# iospear600 register map
Registers are 32-bit, access not given, no defined reset value unless marked. A register's access mark holds for its fields unless they carry their own. Addresses are absolute; registers are grouped by the start of their names; [hi:lo] are bit positions; {n}, {i} and the like mark numbered series; 'fields as' and 'values as' point back to an identical list.

## SFR
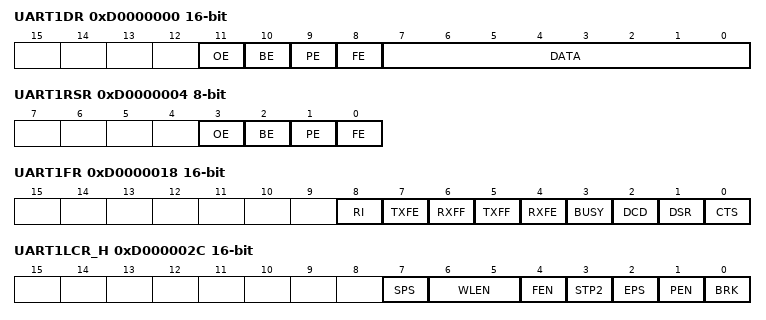
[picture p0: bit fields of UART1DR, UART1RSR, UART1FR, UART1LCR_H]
0xD0000000 UART1DR 16-bit
  [11] OE, [10] BE, [9] PE, [8] FE, [7:0] DATA
0xD0000004 UART1RSR 8-bit
  [3] OE, [2] BE, [1] PE, [0] FE
0xD0000004 UART1ECR 8-bit
0xD0000018 UART1FR 16-bit
  [8] RI, [7] TXFE, [6] RXFF, [5] TXFF, [4] RXFE, [3] BUSY, [2] DCD, [1] DSR, [0] CTS
0xD0000024 UART1IBRD 16-bit
0xD0000028 UART1FBRD 8-bit
  [5:0] DIVFRAC
0xD000002C UART1LCR_H 16-bit
  [7] SPS, [6:5] WLEN, [4] FEN, [3] STP2, [2] EPS, [1] PEN, [0] BRK
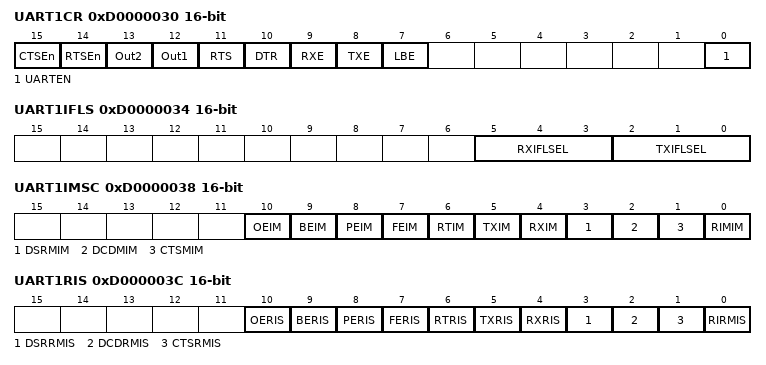
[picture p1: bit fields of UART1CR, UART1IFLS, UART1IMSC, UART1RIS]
0xD0000030 UART1CR 16-bit
  [15] CTSEn, [14] RTSEn, [13] Out2, [12] Out1, [11] RTS, [10] DTR, [9] RXE, [8] TXE, [7] LBE, [0] UARTEN
0xD0000034 UART1IFLS 16-bit
  [5:3] RXIFLSEL, [2:0] TXIFLSEL
0xD0000038 UART1IMSC 16-bit
  [10] OEIM, [9] BEIM, [8] PEIM, [7] FEIM, [6] RTIM, [5] TXIM, [4] RXIM, [3] DSRMIM, [2] DCDMIM, [1] CTSMIM, [0] RIMIM
0xD000003C UART1RIS 16-bit
  [10] OERIS, [9] BERIS, [8] PERIS, [7] FERIS, [6] RTRIS, [5] TXRIS, [4] RXRIS, [3] DSRRMIS, [2] DCDRMIS, [1] CTSRMIS, [0] RIRMIS
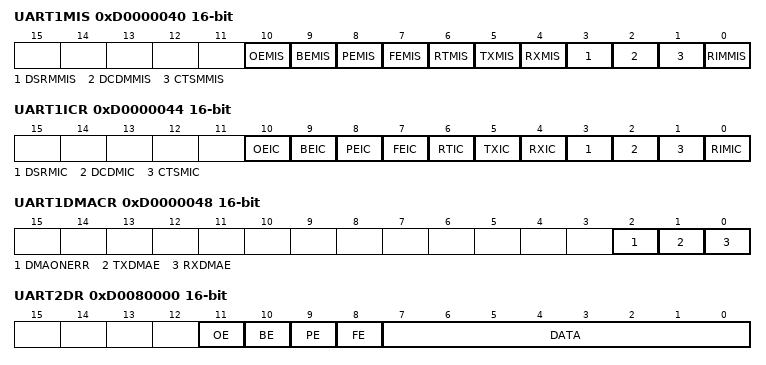
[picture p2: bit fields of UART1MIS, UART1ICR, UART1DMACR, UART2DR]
0xD0000040 UART1MIS 16-bit
  [10] OEMIS, [9] BEMIS, [8] PEMIS, [7] FEMIS, [6] RTMIS, [5] TXMIS, [4] RXMIS, [3] DSRMMIS, [2] DCDMMIS, [1] CTSMMIS, [0] RIMMIS
0xD0000044 UART1ICR 16-bit
  [10] OEIC, [9] BEIC, [8] PEIC, [7] FEIC, [6] RTIC, [5] TXIC, [4] RXIC, [3] DSRMIC, [2] DCDMIC, [1] CTSMIC, [0] RIMIC
0xD0000048 UART1DMACR 16-bit
  [2] DMAONERR, [1] TXDMAE, [0] RXDMAE
{0xD0000FE0+4i} UART1PeriphID{i} (i=0..3)
{0xD0000FF0+4i} UART1PCellID{i} (i=0..3)
0xD0080000 UART2DR 16-bit
  [11] OE, [10] BE, [9] PE, [8] FE, [7:0] DATA
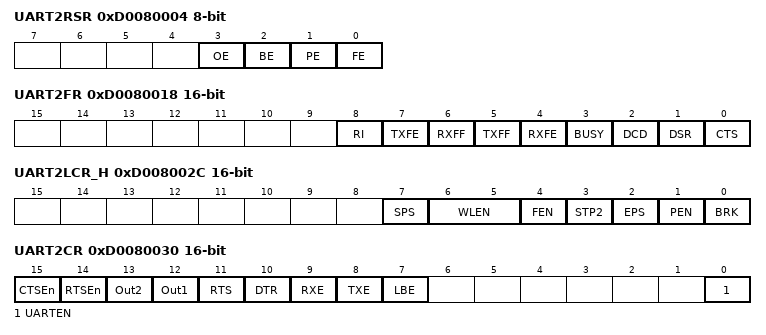
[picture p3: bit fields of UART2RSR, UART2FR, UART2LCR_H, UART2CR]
0xD0080004 UART2RSR 8-bit
  [3] OE, [2] BE, [1] PE, [0] FE
0xD0080004 UART2ECR 8-bit
0xD0080018 UART2FR 16-bit
  fields as UART1FR
0xD0080024 UART2IBRD 16-bit
0xD0080028 UART2FBRD 8-bit
  [5:0] DIVFRAC
0xD008002C UART2LCR_H 16-bit
  [7] SPS, [6:5] WLEN, [4] FEN, [3] STP2, [2] EPS, [1] PEN, [0] BRK
0xD0080030 UART2CR 16-bit
  fields as UART1CR
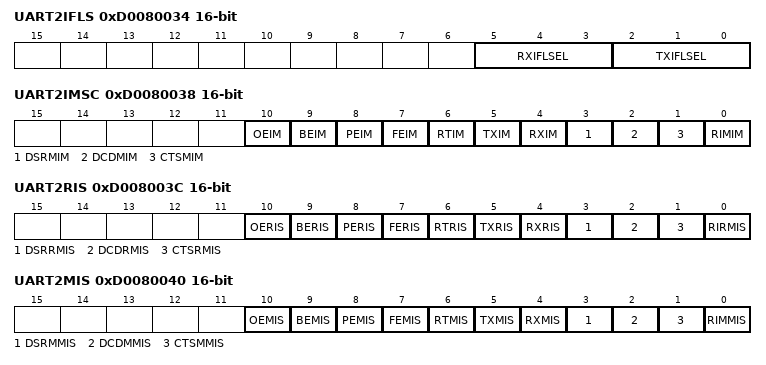
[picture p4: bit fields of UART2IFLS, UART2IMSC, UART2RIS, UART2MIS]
0xD0080034 UART2IFLS 16-bit
  [5:3] RXIFLSEL, [2:0] TXIFLSEL
0xD0080038 UART2IMSC 16-bit
  fields as UART1IMSC
0xD008003C UART2RIS 16-bit
  fields as UART1RIS
0xD0080040 UART2MIS 16-bit
  fields as UART1MIS
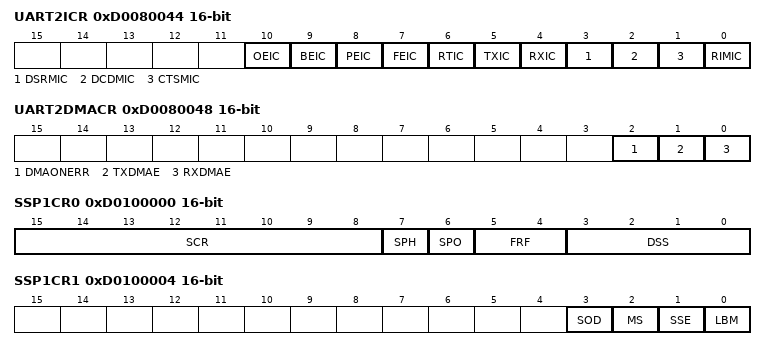
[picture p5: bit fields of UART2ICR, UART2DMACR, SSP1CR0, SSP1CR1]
0xD0080044 UART2ICR 16-bit
  fields as UART1ICR
0xD0080048 UART2DMACR 16-bit
  [2] DMAONERR, [1] TXDMAE, [0] RXDMAE
{0xD0080FE0+4i} UART2PeriphID{i} (i=0..3)
{0xD0080FF0+4i} UART2PCellID{i} (i=0..3)
0xD0100000 SSP1CR0 16-bit
  [15:8] SCR, [7] SPH, [6] SPO, [5:4] FRF, [3:0] DSS
0xD0100004 SSP1CR1 16-bit
  [3] SOD, [2] MS, [1] SSE, [0] LBM
0xD0100008 SSP1DR 16-bit
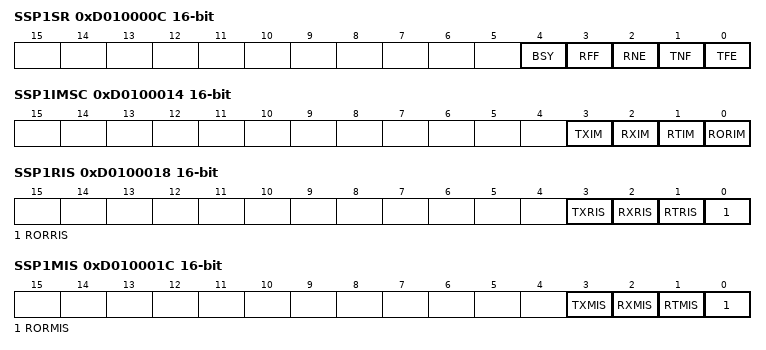
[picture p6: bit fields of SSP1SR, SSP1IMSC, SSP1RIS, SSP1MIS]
0xD010000C SSP1SR 16-bit
  [4] BSY, [3] RFF, [2] RNE, [1] TNF, [0] TFE
0xD0100010 SSP1CPSR 16-bit
  [7:0] CPSDVSR
0xD0100014 SSP1IMSC 16-bit
  [3] TXIM, [2] RXIM, [1] RTIM, [0] RORIM
0xD0100018 SSP1RIS 16-bit
  [3] TXRIS, [2] RXRIS, [1] RTRIS, [0] RORRIS
0xD010001C SSP1MIS 16-bit
  [3] TXMIS, [2] RXMIS, [1] RTMIS, [0] RORMIS
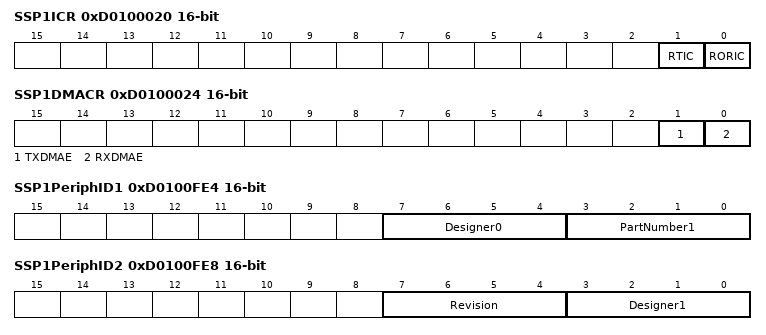
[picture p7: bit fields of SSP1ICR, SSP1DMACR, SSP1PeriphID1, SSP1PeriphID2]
0xD0100020 SSP1ICR 16-bit
  [1] RTIC, [0] RORIC
0xD0100024 SSP1DMACR 16-bit
  [1] TXDMAE, [0] RXDMAE
0xD0100FE0 SSP1PeriphID0 16-bit
  [7:0] PartNumber0
0xD0100FE4 SSP1PeriphID1 16-bit
  [7:4] Designer0, [3:0] PartNumber1
0xD0100FE8 SSP1PeriphID2 16-bit
  [7:4] Revision, [3:0] Designer1
0xD0100FEC SSP1PeriphID3 16-bit
  [7:0] Configuration
{0xD0100FF0+4i} SSP1CellID{i} 16-bit (i=0..3)
  [7:0] PCELLID{i}
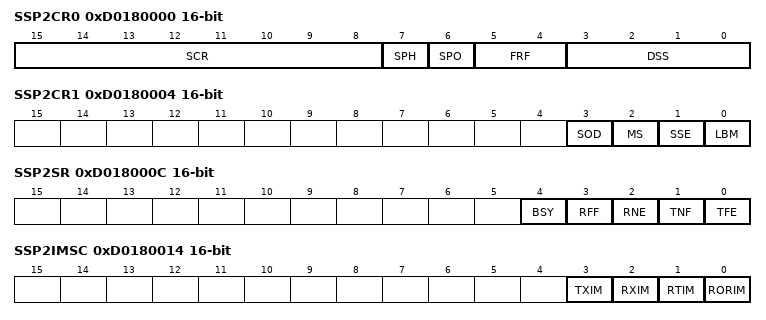
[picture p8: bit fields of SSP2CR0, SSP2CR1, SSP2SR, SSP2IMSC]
0xD0180000 SSP2CR0 16-bit
  [15:8] SCR, [7] SPH, [6] SPO, [5:4] FRF, [3:0] DSS
0xD0180004 SSP2CR1 16-bit
  [3] SOD, [2] MS, [1] SSE, [0] LBM
0xD0180008 SSP2DR 16-bit
0xD018000C SSP2SR 16-bit
  [4] BSY, [3] RFF, [2] RNE, [1] TNF, [0] TFE
0xD0180010 SSP2CPSR 16-bit
  [7:0] CPSDVSR
0xD0180014 SSP2IMSC 16-bit
  [3] TXIM, [2] RXIM, [1] RTIM, [0] RORIM
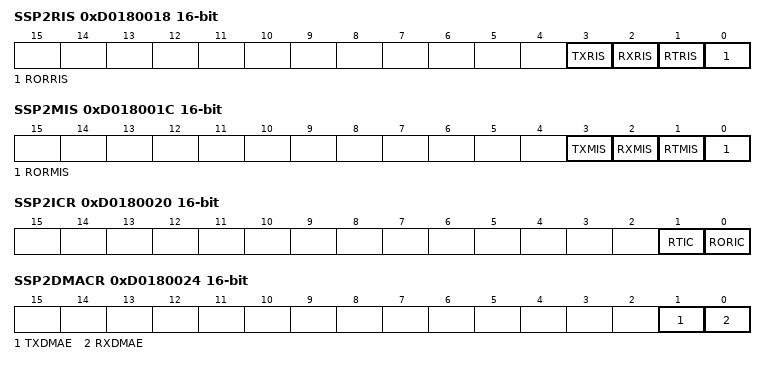
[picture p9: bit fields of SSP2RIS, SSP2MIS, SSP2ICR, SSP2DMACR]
0xD0180018 SSP2RIS 16-bit
  [3] TXRIS, [2] RXRIS, [1] RTRIS, [0] RORRIS
0xD018001C SSP2MIS 16-bit
  [3] TXMIS, [2] RXMIS, [1] RTMIS, [0] RORMIS
0xD0180020 SSP2ICR 16-bit
  [1] RTIC, [0] RORIC
0xD0180024 SSP2DMACR 16-bit
  [1] TXDMAE, [0] RXDMAE
0xD0180FE0 SSP2PeriphID0 16-bit
  [7:0] PartNumber0
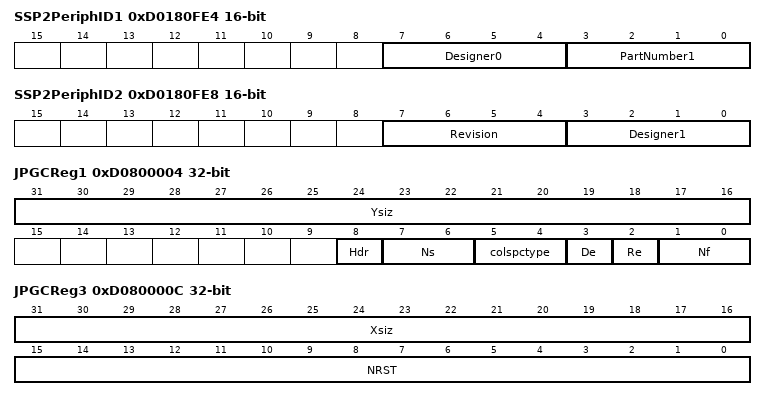
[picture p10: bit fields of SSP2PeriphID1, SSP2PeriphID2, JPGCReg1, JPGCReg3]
0xD0180FE4 SSP2PeriphID1 16-bit
  [7:4] Designer0, [3:0] PartNumber1
0xD0180FE8 SSP2PeriphID2 16-bit
  [7:4] Revision, [3:0] Designer1
0xD0180FEC SSP2PeriphID3 16-bit
  [7:0] Configuration
{0xD0180FF0+4i} SSP2CellID{i} 16-bit (i=0..3)
  [7:0] PCELLID{i}
0xD0800000 JPGCReg0
  [0] StartStop
0xD0800004 JPGCReg1
  [31:16] Ysiz, [8] Hdr, [7:6] Ns, [5:4] colspctype, [3] De, [2] Re, [1:0] Nf
0xD0800008 JPGCReg2
  [25:0] NMCU
0xD080000C JPGCReg3
  [31:16] Xsiz, [15:0] NRST
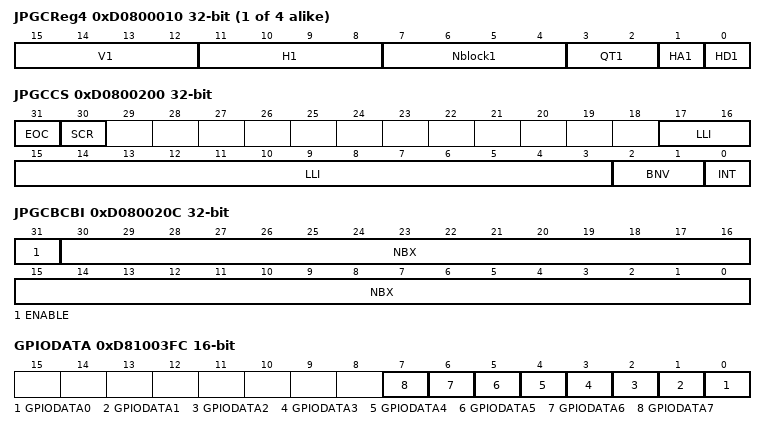
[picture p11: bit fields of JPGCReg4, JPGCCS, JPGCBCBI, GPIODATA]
{0xD0800000+4i} JPGCReg{i} (i=4..7)
  [15:12] V{i-3}, [11:8] H{i-3}, [7:4] Nblock{i-3}, [3:2] QT{i-3}, [1] HA{i-3}, [0] HD{i-3}
0xD0800200 JPGCCS
  [31] EOC, [30] SCR, [17:3] LLI, [2:1] BNV, [0] INT
0xD0800204 JPGCBFIFO2C
0xD0800208 JPGCBC2FIFO
0xD080020C JPGCBCBI
  [31] ENABLE, [30:0] NBX
0xD0800400 JPGCFifoIn
0xD0800600 JPGCFifoOut
0xD0800800 JPGCQMem
0xD0800C00 JPGCHuffMin
0xD0801000 JPGCHuffBase
0xD0801400 JPGCHuffSymb
0xD0801800 JPGCDHTMem
0xD0801C00 JPGCHuffEnc
0xD81003FC GPIODATA 16-bit
  [n] GPIODATA{n} (n=0..7)
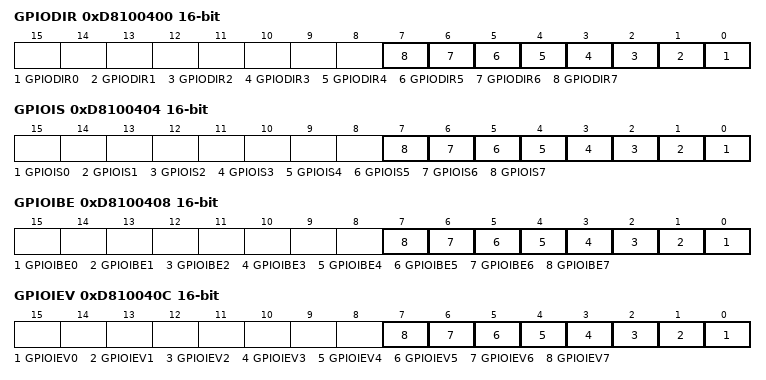
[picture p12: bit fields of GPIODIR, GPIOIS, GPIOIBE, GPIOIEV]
0xD8100400 GPIODIR 16-bit
  [n] GPIODIR{n} (n=0..7)
0xD8100404 GPIOIS 16-bit
  [n] GPIOIS{n} (n=0..7)
0xD8100408 GPIOIBE 16-bit
  [n] GPIOIBE{n} (n=0..7)
0xD810040C GPIOIEV 16-bit
  [n] GPIOIEV{n} (n=0..7)
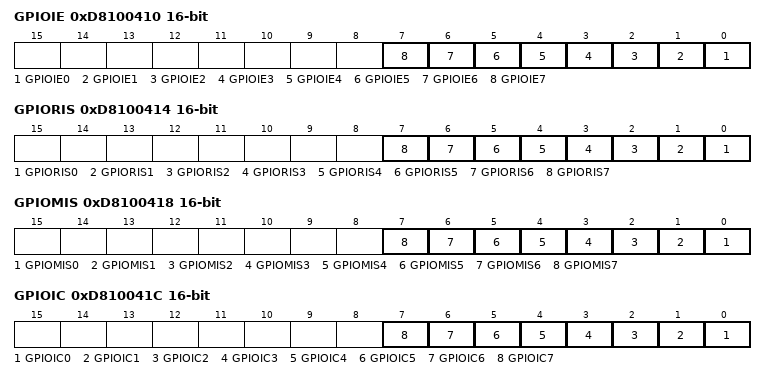
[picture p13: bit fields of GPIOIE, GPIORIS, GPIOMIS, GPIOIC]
0xD8100410 GPIOIE 16-bit
  [n] GPIOIE{n} (n=0..7)
0xD8100414 GPIORIS 16-bit
  [n] GPIORIS{n} (n=0..7)
0xD8100418 GPIOMIS 16-bit
  [n] GPIOMIS{n} (n=0..7)
0xD810041C GPIOIC 16-bit
  [n] GPIOIC{n} (n=0..7)
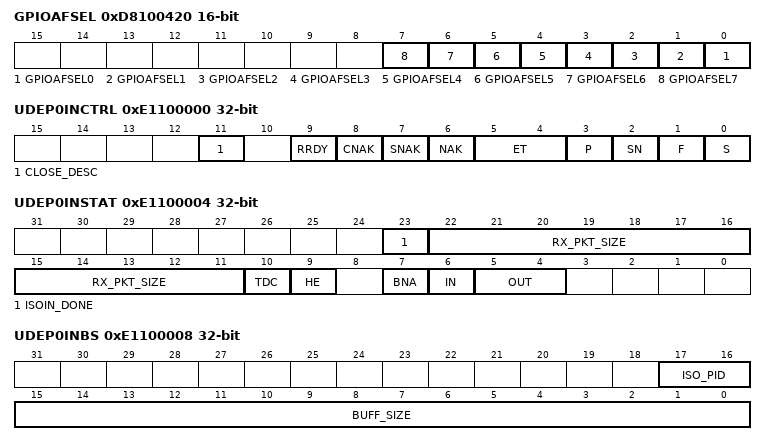
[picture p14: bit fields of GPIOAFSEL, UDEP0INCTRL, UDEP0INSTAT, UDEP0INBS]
0xD8100420 GPIOAFSEL 16-bit
  [n] GPIOAFSEL{n} (n=0..7)
{0xD8100FE0+4i} GPIOPeriphID{i} 16-bit (i=0..3)
{0xD8100FF0+4i} GPIOPCellID{i} 16-bit (i=0..3)
0xE1100000 UDEP0INCTRL
  [11] CLOSE_DESC, [9] RRDY, [8] CNAK, [7] SNAK, [6] NAK, [5:4] ET, [3] P, [2] SN, [1] F, [0] S
0xE1100004 UDEP0INSTAT
  [23] ISOIN_DONE, [22:11] RX_PKT_SIZE, [10] TDC, [9] HE, [7] BNA, [6] IN, [5:4] OUT
0xE1100008 UDEP0INBS
  [17:16] ISO_PID, [15:0] BUFF_SIZE
0xE110000C UDEP0INMPS
  [31:16] BUFF_SIZE, [15:0] MAX_PKT_SIZE
0xE1100014 UDEP0INDDP
0xE1100018 UDEP0INWC
0xE1100020 UDEP1INCTRL
  fields as UDEP0INCTRL
0xE1100024 UDEP1INSTAT
  fields as UDEP0INSTAT
0xE1100028 UDEP1INBS
  [17:16] ISO_PID, [15:0] BUFF_SIZE
0xE110002C UDEP1INMPS
  [31:16] BUFF_SIZE, [15:0] MAX_PKT_SIZE
0xE1100034 UDEP1INDDP
0xE1100038 UDEP1INWC
0xE1100060 UDEP3INCTRL
  fields as UDEP0INCTRL
0xE1100064 UDEP3INSTAT
  fields as UDEP0INSTAT
0xE1100068 UDEP3INBS
  [17:16] ISO_PID, [15:0] BUFF_SIZE
0xE110006C UDEP3INMPS
  [31:16] BUFF_SIZE, [15:0] MAX_PKT_SIZE
0xE1100074 UDEP3INDDP
0xE1100078 UDEP3INWC
0xE11000A0 UDEP5INCTRL
  fields as UDEP0INCTRL
0xE11000A4 UDEP5INSTAT
  fields as UDEP0INSTAT
0xE11000A8 UDEP5INBS
  [17:16] ISO_PID, [15:0] BUFF_SIZE
0xE11000AC UDEP5INMPS
  [31:16] BUFF_SIZE, [15:0] MAX_PKT_SIZE
0xE11000B4 UDEP5INDDP
0xE11000B8 UDEP5INWC
0xE11000E0 UDEP7INCTRL
  fields as UDEP0INCTRL
0xE11000E4 UDEP7INSTAT
  fields as UDEP0INSTAT
0xE11000E8 UDEP7INBS
  [17:16] ISO_PID, [15:0] BUFF_SIZE
0xE11000EC UDEP7INMPS
  [31:16] BUFF_SIZE, [15:0] MAX_PKT_SIZE
0xE11000F4 UDEP7INDDP
0xE11000F8 UDEP7INWC
0xE1100120 UDEP9INCTRL
  fields as UDEP0INCTRL
0xE1100124 UDEP9INSTAT
  fields as UDEP0INSTAT
0xE1100128 UDEP9INBS
  [17:16] ISO_PID, [15:0] BUFF_SIZE
0xE110012C UDEP9INMPS
  [31:16] BUFF_SIZE, [15:0] MAX_PKT_SIZE
0xE1100134 UDEP9INDDP
0xE1100138 UDEP9INWC
0xE1100160 UDEP11INCTRL
  fields as UDEP0INCTRL
0xE1100164 UDEP11INSTAT
  fields as UDEP0INSTAT
0xE1100168 UDEP11INBS
  [17:16] ISO_PID, [15:0] BUFF_SIZE
0xE110016C UDEP11INMPS
  [31:16] BUFF_SIZE, [15:0] MAX_PKT_SIZE
0xE1100174 UDEP11INDDP
0xE1100178 UDEP11INWC
0xE11001A0 UDEP13INCTRL
  fields as UDEP0INCTRL
0xE11001A4 UDEP13INSTAT
  fields as UDEP0INSTAT
0xE11001A8 UDEP13INBS
  [17:16] ISO_PID, [15:0] BUFF_SIZE
0xE11001AC UDEP13INMPS
  [31:16] BUFF_SIZE, [15:0] MAX_PKT_SIZE
0xE11001B4 UDEP13INDDP
0xE11001B8 UDEP13INWC
0xE11001E0 UDEP15INCTRL
  fields as UDEP0INCTRL
0xE11001E4 UDEP15INSTAT
  fields as UDEP0INSTAT
0xE11001E8 UDEP15INBS
  [17:16] ISO_PID, [15:0] BUFF_SIZE
0xE11001EC UDEP15INMPS
  [31:16] BUFF_SIZE, [15:0] MAX_PKT_SIZE
0xE11001F4 UDEP15INDDP
0xE11001F8 UDEP15INWC
0xE1100200 UDEP0OUTCTRL
  fields as UDEP0INCTRL
0xE1100204 UDEP0OUTSTAT
  fields as UDEP0INSTAT
0xE1100208 UDEP0OUTPFN
  [17:16] ISO_PID, [15:0] BUFF_SIZE
0xE110020C UDEP0OUTBS
  [31:16] BUFF_SIZE, [15:0] MAX_PKT_SIZE
0xE1100210 UDEP0OUSBP
0xE1100214 UDEP0OUTDDP
0xE110021C UDEP0OUTRC
0xE1100240 UDEP2OUTCTRL
  fields as UDEP0INCTRL
0xE1100244 UDEP2OUTSTAT
  fields as UDEP0INSTAT
0xE1100248 UDEP2OUTPFN
  [17:16] ISO_PID, [15:0] BUFF_SIZE
0xE110024C UDEP2OUTBS
  [31:16] BUFF_SIZE, [15:0] MAX_PKT_SIZE
0xE1100250 UDEP2OUSBP
0xE1100254 UDEP2OUTDDP
0xE110025C UDEP2OUTRC
0xE1100280 UDEP4OUTCTRL
  fields as UDEP0INCTRL
0xE1100284 UDEP4OUTSTAT
  fields as UDEP0INSTAT
0xE1100288 UDEP4OUTPFN
  [17:16] ISO_PID, [15:0] BUFF_SIZE
0xE110028C UDEP4OUTBS
  [31:16] BUFF_SIZE, [15:0] MAX_PKT_SIZE
0xE1100290 UDEP4OUSBP
0xE1100294 UDEP4OUTDDP
0xE110029C UDEP4OUTRC
0xE11002C0 UDEP6OUTCTRL
  fields as UDEP0INCTRL
0xE11002C4 UDEP6OUTSTAT
  fields as UDEP0INSTAT
0xE11002C8 UDEP6OUTPFN
  [17:16] ISO_PID, [15:0] BUFF_SIZE
0xE11002CC UDEP6OUTBS
  [31:16] BUFF_SIZE, [15:0] MAX_PKT_SIZE
0xE11002D0 UDEP6OUSBP
0xE11002D4 UDEP6OUTDDP
0xE11002DC UDEP6OUTRC
0xE1100300 UDEP8OUTCTRL
  fields as UDEP0INCTRL
0xE1100304 UDEP8OUTSTAT
  fields as UDEP0INSTAT
0xE1100308 UDEP8OUTPFN
  [17:16] ISO_PID, [15:0] BUFF_SIZE
0xE110030C UDEP8OUTBS
  [31:16] BUFF_SIZE, [15:0] MAX_PKT_SIZE
0xE1100310 UDEP8OUSBP
0xE1100314 UDEP8OUTDDP
0xE110031C UDEP8OUTRC
0xE1100340 UDEP10OUTCTRL
  fields as UDEP0INCTRL
0xE1100344 UDEP10OUTSTAT
  fields as UDEP0INSTAT
0xE1100348 UDEP10OUTPFN
  [17:16] ISO_PID, [15:0] BUFF_SIZE
0xE110034C UDEP10OUTBS
  [31:16] BUFF_SIZE, [15:0] MAX_PKT_SIZE
0xE1100350 UDEP10OUSBP
0xE1100354 UDEP10OUTDDP
0xE110035C UDEP10OUTRC
0xE1100380 UDEP12OUTCTRL
  fields as UDEP0INCTRL
0xE1100384 UDEP12OUTSTAT
  fields as UDEP0INSTAT
0xE1100388 UDEP12OUTPFN
  [17:16] ISO_PID, [15:0] BUFF_SIZE
0xE110038C UDEP12OUTBS
  [31:16] BUFF_SIZE, [15:0] MAX_PKT_SIZE
0xE1100390 UDEP12OUSBP
0xE1100394 UDEP12OUTDDP
0xE110039C UDEP12OUTRC
0xE11003C0 UDEP14OUTCTRL
  fields as UDEP0INCTRL
0xE11003C4 UDEP14OUTSTAT
  fields as UDEP0INSTAT
0xE11003C8 UDEP14OUTPFN
  [17:16] ISO_PID, [15:0] BUFF_SIZE
0xE11003CC UDEP14OUTBS
  [31:16] BUFF_SIZE, [15:0] MAX_PKT_SIZE
0xE11003D0 UDEP14OUSBP
0xE11003D4 UDEP14OUTDDP
0xE11003DC UDEP14OUTRC
0xE1100400 UDDCFG
  [18] SET_DESC, [17] CSR_PRG, [16] HALT_STATUS, [15:13] HS_TIMEOUT_CALIB, [12:10] FS_TIMEOUT_CALIB, [9] PHY_ERROR_DETECT, [8] STATUS_1, [7] STATUS, [6] DIR, [5] PI, [4] SS, [3] SP, [2] RWKP, [1:0] SPD
0xE1100404 UDDCTRL
  [31:24] THLEN, [23:16] BRLEN, [13] CSR_DONE, [12] DEVNAK, [11] SCALE, [10] SD, [9] MODE, [8] BREN, [7] THE, [6] BF, [5] BE, [4] DU, [3] TDE, [2] RDE, [0] RES
0xE1100408 UDDSTAT
  [31:18] TS, [16] PHY_ERROR, [15] RXFIFO_EMPTY, [14:13] ENUM_SPD, [12] SUSP, [11:8] ALT, [7:4] INTF, [3:0] CFG
0xE110040C UDDINTR
  [6] ENUM, [5] SOF, [4] US, [3] UR, [2] ES, [1] SI, [0] SC
0xE1100410 UDDIM
  [6] ENUM, [5] SOF, [4] US, [3] UR, [2] ES, [1] SI, [0] SC
0xE1100414 UDEINTR
  [n+16] OUT_EP{n} (n=0..15), [n] IN_EP{n} (n=0..15)
0xE1100418 UDEIM
  [n+16] OUT_EP{n} (n=0..15), [n] IN_EP{n} (n=0..15)
{0xE1100504+4i} UDEP{i} (i=0..15)
  [29:19] MaxPackSize, [18:15] AltSetting, [14:11] InterfNumber, [10:7] ConfNumber, [6:5] EPType, [4] EPDir, [3:0] EPNumber
0xE1800000 HC1CAPBASE
  [31:16] HCIVERSION, [7:0] CAPLENGTH
0xE1800004 HC1SPARAMS
  [23:20] DPN, [16] P_INDICATOR, [15:12] N_CC, [11:8] N_PCC, [7] PRR, [4] PPC, [3:0] N_PORTS
0xE1800008 HC1CPARAMS
  [15:8] EECP, [7:4] IST, [2] ASPC, [1] PFLF, [0] _64BAC
0xE1800010 HC1USBCMD
  [23:16] ITC, [11] ASPME, [9:8] ASPMC, [7] LHCR, [6] IAAD, [5] ASE, [4] PSE, [3:2] FLS, [1] HCRESET, [0] RS
0xE1800014 HC1USBSTS
  [15] ASS, [14] PSS, [13] R, [12] HH, [5] IAA, [4] HSE, [3] FLR, [2] PCD, [1] USBERRINT, [0] USBINT
0xE1800018 HC1USBINTR
  [5] IAAE, [4] HSEE, [3] FLRE, [2] PCIE, [1] EIE, [0] IE
0xE180001C HC1FRINDEX
  [13:0] FRAME
0xE1800024 HC1PERIODICLISTBASE
0xE1800028 HC1ASYNCLISTADDR
0xE1800050 HC1CONFIGFLAG
  [0] CF
0xE1800054 HC1PORTSC1
  [22] WKOC_E, [21] WKDSCNNT_E, [20] WKCNNT_E, [19:16] PTC, [15:14] PIC, [13] PO, [12] PP, [11:10] LS, [8] PR, [7] S, [6] FPR, [5] OcC, [4] OcA, [3] PEDC, [2] PEN, [1] CSC, [0] CCS
0xE1800090 HC1INSNREG00
  [12:1] PMBV, [0] IN
0xE1800094 HC1INSNREG01
  [31:16] OUT, [15:0] IN
0xE1800098 HC1INSNREG02
  [11:0] DEEP
0xE180009C HC1INSNREG03
  [0] BMT
0xE18000A4 HC1INSNREG05
  [17] VBusy, [16:13] VPort, [12] VControlLoadM, [11:8] VControl, [7:0] VStatus
0xE1900000 Hc1Revision
  [7:0] REV
0xE1900004 Hc1Control
  [10] RWE, [9] RWC, [8] IR, [7:6] HCFS, [5] BLE, [4] CLE, [3] IE, [2] PLE, [1:0] CBSR
0xE1900008 Hc1CommandStatus
  [17:16] SOC, [3] OCR, [2] BLF, [1] CLF, [0] HCR
0xE190000C Hc1InterruptStatus
  [30] OC, [6] RHSC, [5] FNO, [4] UE, [3] RD, [2] SF, [1] WDH, [0] SO
0xE1900010 Hc1InterruptEnable
  [31] MIE, [30] OC, [6] RHSC, [5] FNO, [4] UE, [3] RD, [2] SF, [1] WDH, [0] SO
0xE1900014 Hc1InterruptDisable
  fields as Hc1InterruptEnable
0xE1900018 Hc1HCCA
  [31:8] HCCA
0xE190001C Hc1PeriodCurrentED
  [31:4] PCED
0xE1900020 Hc1ControlHeadED
  [31:4] CHED
0xE1900024 Hc1ControlCurrentED
  [31:4] CCED
0xE1900028 Hc1BulkHeadED
  [31:4] BHED
0xE190002C Hc1BulkCurrentED
  [31:4] BCED
0xE1900030 Hc1DoneHead
  [31:4] DH
0xE1900034 Hc1FmInterval
  [31] FIT, [30:16] FSMPS, [13:0] FI
0xE1900038 Hc1FmRemaining
  [31] FRT, [13:0] FR
0xE190003C Hc1FmNumber
  [15:0] FN
0xE1900040 Hc1PeriodStart
  [13:0] PS
0xE1900044 Hc1LSThreshold
  [11:0] LST
0xE1900048 Hc1RhDescriptorA
  [31:24] POTPGT, [12] NOCP, [11] OCPM, [10] DT, [9] NPS, [8] PSM, [7:0] NDP
0xE190004C Hc1RhDescripterB
  [31:16] PPCM, [15:0] DR
0xE1900050 Hc1RhStatus
  [31] CRWE, [17] OCIC, [16] LPSC, [15] DRWE, [1] OCI, [0] LPS
0xE1900054 Hc1RhPortStatus
  [20] PRSC, [19] OCIC, [18] PSSC, [17] PESC, [16] CSC, [9] LSDA, [8] PPS, [4] PRS, [3] POCI, [2] PSS, [1] PES, [0] CCS
0xE2000000 HC2CAPBASE
  [31:16] HCIVERSION, [7:0] CAPLENGTH
0xE2000004 HC2SPARAMS
  fields as HC1SPARAMS
0xE2000008 HC2CPARAMS
  [15:8] EECP, [7:4] IST, [2] ASPC, [1] PFLF, [0] _64BAC
0xE2000010 HC2USBCMD
  fields as HC1USBCMD
0xE2000014 HC2USBSTS
  fields as HC1USBSTS
0xE2000018 HC2USBINTR
  [5] IAAE, [4] HSEE, [3] FLRE, [2] PCIE, [1] EIE, [0] IE
0xE200001C HC2FRINDEX
  [13:0] FRAME
0xE2000024 HC2PERIODICLISTBASE
0xE2000028 HC2ASYNCLISTADDR
0xE2000050 HC2CONFIGFLAG
  [0] CF
0xE2000054 HC2PORTSC1
  fields as HC1PORTSC1
0xE2000090 HC2INSNREG00
  [12:1] PMBV, [0] IN
0xE2000094 HC2INSNREG01
  [31:16] OUT, [15:0] IN
0xE2000098 HC2INSNREG02
  [11:0] DEEP
0xE200009C HC2INSNREG03
  [0] BMT
0xE20000A4 HC2INSNREG05
  fields as HC1INSNREG05
0xE2100000 Hc2Revision
  [7:0] REV
0xE2100004 Hc2Control
  fields as Hc1Control
0xE2100008 Hc2CommandStatus
  [17:16] SOC, [3] OCR, [2] BLF, [1] CLF, [0] HCR
0xE210000C Hc2InterruptStatus
  [30] OC, [6] RHSC, [5] FNO, [4] UE, [3] RD, [2] SF, [1] WDH, [0] SO
0xE2100010 Hc2InterruptEnable
  fields as Hc1InterruptEnable
0xE2100014 Hc2InterruptDisable
  fields as Hc1InterruptEnable
0xE2100018 Hc2HCCA
  [31:8] HCCA
0xE210001C Hc2PeriodCurrentED
  [31:4] PCED
0xE2100020 Hc2ControlHeadED
  [31:4] CHED
0xE2100024 Hc2ControlCurrentED
  [31:4] CCED
0xE2100028 Hc2BulkHeadED
  [31:4] BHED
0xE210002C Hc2BulkCurrentED
  [31:4] BCED
0xE2100030 Hc2DoneHead
  [31:4] DH
0xE2100034 Hc2FmInterval
  [31] FIT, [30:16] FSMPS, [13:0] FI
0xE2100038 Hc2FmRemaining
  [31] FRT, [13:0] FR
0xE210003C Hc2FmNumber
  [15:0] FN
0xE2100040 Hc2PeriodStart
  [13:0] PS
0xE2100044 Hc2LSThreshold
  [11:0] LST
0xE2100048 Hc2RhDescriptorA
  fields as Hc1RhDescriptorA
0xE210004C Hc2RhDescripterB
  [31:16] PPCM, [15:0] DR
0xE2100050 Hc2RhStatus
  [31] CRWE, [17] OCIC, [16] LPSC, [15] DRWE, [1] OCI, [0] LPS
0xE2100054 Hc2RhPortStatus
  fields as Hc1RhPortStatus
0xF01003FC GPIOMLDATA 16-bit
  [n] GPIODATA{n} (n=0..7)
0xF0100400 GPIOMLDIR 16-bit
  [n] GPIODIR{n} (n=0..7)
0xF0100404 GPIOMLIS 16-bit
  [n] GPIOIS{n} (n=0..7)
0xF0100408 GPIOMLIBE 16-bit
  [n] GPIOIBE{n} (n=0..7)
0xF010040C GPIOMLIEV 16-bit
  [n] GPIOIEV{n} (n=0..7)
0xF0100410 GPIOMLIE 16-bit
  [n] GPIOIE{n} (n=0..7)
0xF0100414 GPIOMLRIS 16-bit
  [n] GPIORIS{n} (n=0..7)
0xF0100418 GPIOMLMIS 16-bit
  [n] GPIOMIS{n} (n=0..7)
0xF010041C GPIOMLIC 16-bit
  [n] GPIOIC{n} (n=0..7)
0xF0100420 GPIOMLAFSEL 16-bit
  [n] GPIOAFSEL{n} (n=0..7)
{0xF0100FE0+4i} GPIOMLPeriphID{i} 16-bit (i=0..3)
{0xF0100FF0+4i} GPIOMLPCellID{i} 16-bit (i=0..3)
0xF1000000 VIC1IRQSTATUS
  [n] IRQStatus{n} (n=0..31)
0xF1000004 VIC1FIQSTATUS
  [n] FIQStatus{n} (n=0..31)
0xF1000008 VIC1RAWINTR
  [n] RawStatus{n} (n=0..31)
0xF100000C VIC1INTSELECT
  [n] IntSelect{n} (n=0..31)
0xF1000010 VIC1INTENABLE
  [n] IntEnable{n} (n=0..31)
0xF1000014 VIC1INTENCLEAR
  [n] IntEnableClear{n} (n=0..31)
0xF1000018 VIC1SOFTINT
  [n] SoftInt{n} (n=0..31)
0xF100001C VIC1SOFTINTCLEAR
  [n] SoftIntClear{n} (n=0..31)
0xF1000020 VIC1PROTECTION
  [0] Protection
0xF1000030 VIC1VECTADDR
0xF1000034 VIC1DEFVECTADDR
{0xF1000100+4i} VIC1VECTADDR{i} (i=0..15)
{0xF1000200+4i} VIC1VECTCNTL{i} (i=0..15)
  [5] E, [4:0] IntSource
0xF1000FE0 VIC1PERIPHID0 8-bit
0xF1000FE4 VIC1PERIPHID1 8-bit
  [7:4] Designer, [3:0] Partnumber
0xF1000FE8 VIC1PERIPHID2 8-bit
  [7:4] Revision, [3:0] Designer
0xF1000FEC VIC1PERIPHID3 8-bit
{0xF1000FF0+4i} VIC1PCELLID{i} 8-bit (i=0..3)
0xF1100000 VIC0IRQSTATUS
  [n] IRQStatus{n} (n=0..31)
0xF1100004 VIC0FIQSTATUS
  [n] FIQStatus{n} (n=0..31)
0xF1100008 VIC0RAWINTR
  [n] RawStatus{n} (n=0..31)
0xF110000C VIC0INTSELECT
  [n] IntSelect{n} (n=0..31)
0xF1100010 VIC0INTENABLE
  [n] IntEnable{n} (n=0..31)
0xF1100014 VIC0INTENCLEAR
  [n] IntEnableClear{n} (n=0..31)
0xF1100018 VIC0SOFTINT
  [n] SoftInt{n} (n=0..31)
0xF110001C VIC0SOFTINTCLEAR
  [n] SoftIntClear{n} (n=0..31)
0xF1100020 VIC0PROTECTION
  [0] Protection
0xF1100030 VIC0VECTADDR
0xF1100034 VIC0DEFVECTADDR
{0xF1100100+4i} VIC0VECTADDR{i} (i=0..15)
{0xF1100200+4i} VIC0VECTCNTL{i} (i=0..15)
  [5] E, [4:0] IntSource
0xF1100FE0 VIC0PERIPHID0 8-bit
0xF1100FE4 VIC0PERIPHID1 8-bit
  [7:4] Designer, [3:0] Partnumber
0xF1100FE8 VIC0PERIPHID2 8-bit
  [7:4] Revision, [3:0] Designer
0xF1100FEC VIC0PERIPHID3 8-bit
{0xF1100FF0+4i} VIC0PCELLID{i} 8-bit (i=0..3)
0xFC200000 LCDTiming0
  [31:24] HBP, [23:16] HFP, [15:8] HSW, [7:2] PPL
0xFC200004 LCDTiming1
  [31:24] VBP, [23:16] VFP, [15:10] VSW, [9:0] LPP
0xFC200008 LCDTiming2
  [31:27] PCD_HI, [26] BCD, [25:16] CPL, [14] IEO, [13] IPC, [12] IHS, [11] IVS, [10:6] ACB, [5] CLKSEL, [4:0] PCD_LO
0xFC20000C LCDTiming3
  [16] LEE, [6:0] LED
0xFC200010 LCDUPBase
0xFC200014 LCDLPBase
0xFC200018 LCDMSC
  [4] MBERRINTRENB, [3] VCOMPINTRENB, [2] LNBUINTRENB, [1] FUFINTRENB
0xFC20001C LCDControl
  [16] WATERMARK, [13:12] LCDVCOMP, [11] LCDPWR, [10] BEPO, [9] BEBO, [8] BGR, [7] LCDDUAL, [6] LCDMONO8, [5] LCDTFT, [4] LCDBW, [3:1] LCDBPP, [0] LCDEN
0xFC200020 LCDRIS
  [4] MBERROR, [3] VCOMP, [2] LNBU, [1] FUF
0xFC200024 LCDMIS
  [4] MBERRORINTR, [3] VCOMPINTR, [2] LNBUINTR, [1] FUFINTR
0xFC200028 LCDICR
  [4] MBERROR, [3] VCOMP, [2] LNBU, [1] FUF
0xFC20002C LCDUPCUR
0xFC200030 LCDLPCUR
0xFC200200 LCDPaletteBase
{0xFC200FE0+4i} LCDLPHERIPHID{i} (i=0..3)
{0xFC200FF0+4i} LCDLPCELLIDID{i} (i=0..3)
0xFC400000 DMACIntStatus
  [n] IntStatus{n} (n=0..7)
0xFC400004 DMACIntTCStatus
  [n] IntTCStatus{n} (n=0..7)
0xFC400008 DMACIntTCClear
  [n] IntTCClear{n} (n=0..7)
0xFC40000C DMACIntErrorStatus
  [n] IntErrorStatus{n} (n=0..7)
0xFC400010 DMACIntErrClr
  [n] IntErrClr{n} (n=0..7)
0xFC400014 DMACRawIntTCStatus
  [n] RawIntTCStatus{n} (n=0..7)
0xFC400018 DMACRawIntErrorStatus
  [n] RawIntErrorStatus{n} (n=0..7)
0xFC40001C DMACEnbldChns
  [n] EnabledChannels{n} (n=0..7)
0xFC400020 DMACSoftBReq
  [n] SoftBReq{n} (n=0..15)
0xFC400024 DMACSoftSReq
  [n] SoftSReq{n} (n=0..15)
0xFC400028 DMACSoftLBReq
  [n] SoftLBReq{n} (n=0..15)
0xFC40002C DMACSoftLSReq
  [n] SoftLSReq{n} (n=0..15)
0xFC400030 DMACConfiguration
  [2] M2, [1] M1, [0] E
0xFC400034 DMACSync
  [n] DMACSync{n} (n=0..15)
{0xFC400100+0x20*i} DMACC{i}SrcAddr (i=0..7)
{0xFC400104+0x20*i} DMACC{i}DestAddr (i=0..7)
{0xFC400108+0x20*i} DMACC{i}LLI (i=0..7)
  [31:2] LLI, [0] LM
{0xFC40010C+0x20*i} DMACC{i}Control (i=0..7)
  [31] I, [30:28] Port, [27] DI, [26] SI, [25] D, [24] S, [23:21] Dwidth, [20:18] Swidth, [17:15] DBSize, [14:12] SBSize, [11:0] TS
{0xFC400110+0x20*i} DMACC{i}Configuration (i=0..7)
  [18] H, [17] A, [16] L, [15] ITC, [14] IE, [13:11] FlowCntrl, [9:6] DestPeripheral, [4:1] SrcPeripheral, [0] E
{0xFC400FE0+4i} DMACPeriphID{i} (i=0..3)
{0xFC400FF0+4i} DMACPCellID{i} (i=0..3)
0xFC600000 MEM0_CTL
  [25:24] ahb2_fifo_typ_reg, [17:16] ahb1_fifo_typ_reg, [9:8] ahb0_fifo_typ_reg, [0] add_cmp_en
0xFC600004 MEM1_CTL
  [8n-23:8n-24] ahb{n}_fifo_typ_reg (n=3..6)
0xFC600008 MEM2_CTL
  [24] bank_split_en, [16] auto_resfreh_mod, [8] arefresh, [0] ap
0xFC60000C MEM3_CTL
  [24] dll_bypass_mode, [16] dll_lockreg, [8] ddr2_ddr1_mode, [0] concurrentap
0xFC600010 MEM4_CTL
  [24] intrptapburst, [16] fast_write, [8] eight_bank_mode, [0] dqs_n_en
0xFC600014 MEM5_CTL
  [24] odt_ad_turn_clken, [16] no_cmd_init, [8] intrptwritea, [0] intrptreada
0xFC600018 MEM6_CTL
  [24] reduce, [16] priority_en, [8] power_down, [0] placement_en
0xFC60001C MEM7_CTL
  [24] start, [16] srefresh, [8] rw_same_en, [0] reg_dimm_enable
0xFC600020 MEM8_CTL
  [24] write_modereg, [16] writeinterp, [8] wgth_rrb_lat_ctrl, [0] tras_lockout
0xFC600024 MEM9_CTL
  [9:8] max_cs_reg, [1:0] cs_map
0xFC600028 MEM10_CTL
  [25:24] rtt_0, [17:16] out_of_range_type, [9:8] odt_wr_map_cs1, [1:0] odt_wr_map_cs0
0xFC60002C MEM11_CTL
  [26:24] ahb0_r_priority, [18:16] ahb0_prt_ordering, [10:8] addr_pins, [1:0] rtt_pad_terminat
0xFC600030 MEM12_CTL
  [26:24] ahb1_w_priority, [18:16] ahb1_r_priority, [10:8] ahb1_prt_ordering, [2:0] ahb0_w_priority
0xFC600034 MEM13_CTL
  [26:24] ahb3_prt_ordering, [18:16] ahb2_w_priority, [10:8] ahb2_r_priority, [2:0] ahb2_prt_ordering
0xFC600038 MEM14_CTL
  [26:24] ahb4_r_priority, [18:16] ahb4_prt_ordering, [10:8] ahb3_w_priority, [2:0] ahb3_r_priority
0xFC60003C MEM15_CTL
  [26:24] ahb5_w_priority, [18:16] ahb5_r_priority, [10:8] ahb5_prt_ordering, [2:0] ahb4_w_priority
0xFC600040 MEM16_CTL
  [26:24] bstlen, [18:16] ahb6_w_priority, [10:8] ahb6_r_priority, [2:0] ahb6_prt_ordering
0xFC600044 MEM17_CTL
  [26:24] tcke, [18:16] out_of_rng_src_id, [10:8] column_size, [2:0] caslat
0xFC600048 MEM18_CTL
  [26:24] trtp, [18:16] trrd, [10:8] tpdex, [2:0] temrs
0xFC60004C MEM19_CTL
  [26:24] wrlat, [18:16] wgt_rrb_wgt_shar, [10:8] twtr, [2:0] twr_int
0xFC600050 MEM20_CTL
  [28:24] ahb0_pry2_rel_pry, [20:16] ahb0_pry1_rel_pry, [12:8] ahb0_pry0_rel_pry, [5:0] age_count
0xFC600054 MEM21_CTL
  [8n-20:8n-24] ahb0_pry{n}_rel_pry (n=3..6)
0xFC600058 MEM22_CTL
  [28:24] ahb1_pry2_rel_pry, [20:16] ahb1_pry1_rel_pry, [12:8] ahb1_pry0_rel_pry, [4:0] ahb0_pry7_rel_pry
0xFC60005C MEM23_CTL
  [8n-20:8n-24] ahb1_pry{n}_rel_pry (n=3..6)
0xFC600060 MEM24_CTL
  [28:24] ahb2_pry2_rel_pry, [20:16] ahb2_pry1_rel_pry, [12:8] ahb2_pry0_rel_pry, [4:0] ahb1_pry7_rel_pry
0xFC600064 MEM25_CTL
  [8n-20:8n-24] ahb2_pry{n}_rel_pry (n=3..6)
0xFC600068 MEM26_CTL
  [28:24] ahb3_pry2_rel_pry, [20:16] ahb3_pry1_rel_pry, [12:8] ahb3_pry0_rel_pry, [4:0] ahb2_pry7_rel_pry
0xFC60006C MEM27_CTL
  [8n-20:8n-24] ahb3_pry{n}_rel_pry (n=3..6)
0xFC600070 MEM28_CTL
  [28:24] ahb4_pry2_rel_pry, [20:16] ahb4_pry1_rel_pry, [12:8] ahb4_pry0_rel_pry, [4:0] ahb3_pry7_rel_pry
0xFC600074 MEM29_CTL
  [8n-20:8n-24] ahb4_pry{n}_rel_pry (n=3..6)
0xFC600078 MEM30_CTL
  [28:24] ahb5_pry2_rel_pry, [20:16] ahb5_pry1_rel_pry, [12:8] ahb5_pry0_rel_pry, [4:0] ahb4_pry7_rel_pry
0xFC60007C MEM31_CTL
  [8n-20:8n-24] ahb5_pry{n}_rel_pry (n=3..6)
0xFC600080 MEM32_CTL
  [28:24] ahb6_pry2_rel_pry, [20:16] ahb6_pry1_rel_pry, [12:8] ahb6_pry0_rel_pry, [4:0] ahb5_pry7_rel_pry
0xFC600084 MEM33_CTL
  [8n-20:8n-24] ahb6_pry{n}_rel_pry (n=3..6)
0xFC600088 MEM34_CTL
  [28:24] caslat_lin_gate, [20:16] caslat_lin, [11:8] aprebit, [4:0] ahb6_pry7_rel_pry
0xFC60008C MEM35_CTL
  [27:24] max_row_reg, [19:16] max_col_reg, [11:8] initaref, [5:0] comd_age_count
0xFC600090 MEM36_CTL
  [27:24] wrr_prm_val_err, [19:16] trp, [11:8] tdal, [3:0] q_fullness
0xFC600094 MEM37_CTL
  [28:24] tfaw, [20:16] ocd_adj_pup_cs, [12:8] ocd_adj_pdn_cs, [5:0] int_ack
0xFC600098 MEM38_CTL
  [30:24] int_status, [22:16] int_mask, [12:8] trc, [4:0] tmrd
0xFC60009C MEM39_CTL
  [14:8] dll_dqs_delay_1, [6:0] dll_dqs_delay_0
0xFC6000A0 MEM40_CTL
  [30:24] dqs_out_shift
0xFC6000A4 MEM41_CTL
  [22:16] wr_dqs_shift, [14:8] dqs_out_shift
0xFC6000A8 MEM42_CTL
  [31:24] trfc, [23:16] trcd_int, [15:8] tras_min, [7:0] tcpd
{0xFC600000+4i} MEM{i}_CTL (i=43..45)
  [26:16] ahb{2i-85}_pry_relax, [10:0] ahb{2i-86}_pry_relax
0xFC6000B8 MEM46_CTL
  [26:16] OUT_OF_RANGE_LENGTH, [10:0] ahb6_pry_relax
{0xFC600000+4i} MEM{i}_CTL (i=47..52)
  [26:16] ahb{i-47}_wrcnt, [10:0] ahb{i-47}_rdcnt
0xFC6000D4 MEM53_CTL
  [26:16] ahb5_wrcnt, [10:0] ahb5_rdcnt
0xFC6000D8 MEM54_CTL
  [30:16] emrs2_data, [13:0] tref
0xFC6000DC MEM55_CTL
  [30:16] emrs_data, [14:0] emrs3_data
0xFC6000E0 MEM56_CTL
  [31:16] TRAS_MAX, [15:0] TDLL
0xFC6000E4 MEM57_CTL
  [31:16] txsr, [15:0] txsnr
0xFC6000E8 MEM58_CTL
  [15:0] version
0xFC6000EC MEM59_CTL
  [23:0] tinit
0xFC6000F0 MEM60_CTL
0xFC6000F4 MEM61_CTL
  [25:24] ahb0_rng_typ1, [17:16] ahb0_rng_typ0, [8] prt_addr_prot_enb, [1:0] out_rng_addr
{0xFC600000+4i} MEM{i}_CTL (i=62..64)
  [25:24] ahb{2i-122}_rng_typ1, [17:16] ahb{2i-122}_rng_typ0, [9:8] ahb{2i-123}_rng_typ1, [1:0] ahb{2i-123}_rng_typ0
0xFC600104 MEM65_CTL
  [24:16] dll_dqs_dly_byps0, [11:8] port_err_type, [2:0] port_err_prt_num
0xFC600108 MEM66_CTL
  [24:16] dll_increment, [8:0] dll_dqs_dly_byps1
0xFC60010C MEM67_CTL
  [24:16] dll_start_point, [8:0] dll_lock
0xFC600110 MEM68_CTL
  [24:16] wr_dqs_shft_byps, [8:0] dqs_out_shft_byps
0xFC600114 MEM69_CTL
  [21:0] ahb0_end_addr0
0xFC600118 MEM70_CTL
  [21:0] ahb0_end_addr1
0xFC60011C MEM71_CTL
  [21:0] ahb0_str_addr0
0xFC600120 MEM72_CTL
  [21:0] ahb0_str_addr1
0xFC600124 MEM73_CTL
  [21:0] ahb1_end_addr0
0xFC600128 MEM74_CTL
  [21:0] ahb1_end_addr1
0xFC60012C MEM75_CTL
  [21:0] ahb1_str_addr0
0xFC600130 MEM76_CTL
  [21:0] ahb1_str_addr1
0xFC600134 MEM77_CTL
  [21:0] ahb2_end_addr0
0xFC600138 MEM78_CTL
  [21:0] ahb2_end_addr1
0xFC60013C MEM79_CTL
  [21:0] ahb2_str_addr0
0xFC600140 MEM80_CTL
  [21:0] ahb2_str_addr1
0xFC600144 MEM81_CTL
  [21:0] ahb3_end_addr0
0xFC600148 MEM82_CTL
  [21:0] ahb3_end_addr1
0xFC60014C MEM83_CTL
  [21:0] ahb3_str_addr0
0xFC600150 MEM84_CTL
  [21:0] ahb3_str_addr1
0xFC600154 MEM85_CTL
  [21:0] ahb4_end_addr0
0xFC600158 MEM86_CTL
  [21:0] ahb4_end_addr1
0xFC60015C MEM87_CTL
  [21:0] ahb4_str_addr0
0xFC600160 MEM88_CTL
  [21:0] ahb4_str_addr1
0xFC600164 MEM89_CTL
  [21:0] ahb5_end_addr0
0xFC600168 MEM90_CTL
  [21:0] ahb5_end_addr1
0xFC60016C MEM91_CTL
  [21:0] ahb5_str_addr0
0xFC600170 MEM92_CTL
  [21:0] ahb5_str_addr1
0xFC600174 MEM93_CTL
  [21:0] ahb6_end_addr0
0xFC600178 MEM94_CTL
  [21:0] ahb6_end_addr1
0xFC60017C MEM95_CTL
  [21:0] ahb6_str_addr0
0xFC600180 MEM96_CTL
  [21:0] ahb6_str_addr1
{0xFC600000+4i} MEM{i}_CTL (i=97..99)
0xFC880000 WdogLoad
0xFC880004 WdogValue
0xFC880008 WdogControl
  [1] RESEN, [0] INTEN
0xFC88000C WdogIntClr
0xFC880010 WdogRIS
  [0] WDOGRIS
0xFC880018 WdogMIS
  [0] WDOGMIS
0xFC880C00 WdogLock
{0xFC880FE0+4i} WdogPeriphID{i} (i=0..3)
{0xFC880FF0+4i} WdogPCellID{i} (i=0..3)
0xFC900000 RTCTIME
  [21:20] HT, [19:16] HU, [14:12] MT, [11:8] MU, [6:4] ST, [3:0] SU
0xFC900004 RTCDATE
  [31:28] YM, [27:24] YH, [23:20] YT, [19:16] YU, [14:12] MT, [11:8] MU, [5:4] DT, [3:0] DU
0xFC900008 RTCALARMTIME
  [21:20] HT, [19:16] HU, [14:12] MT, [11:8] MU, [6:4] ST, [3:0] SU
0xFC90000C RTCALARMDATE
  fields as RTCDATE
0xFC900010 RTCCONTROL
  [31] IE, [9] TB, [8] PB, [5:0] MASK
0xFC900014 RTCSTATUS
  [31] I, [5] LD, [4] LT, [3] PD, [2] PT, [0] RC
0xFC900018 RTCREG1MC
0xFC90001C RTCREG2MC
0xFC9803FC GPIOBDATA 16-bit
  [n] GPIODATA{n} (n=0..7)
0xFC980400 GPIOBDIR 16-bit
  [n] GPIODIR{n} (n=0..7)
0xFC980404 GPIOBIS 16-bit
  [n] GPIOIS{n} (n=0..7)
0xFC980408 GPIOBIBE 16-bit
  [n] GPIOIBE{n} (n=0..7)
0xFC98040C GPIOBIEV 16-bit
  [n] GPIOIEV{n} (n=0..7)
0xFC980410 GPIOBIE 16-bit
  [n] GPIOIE{n} (n=0..7)
0xFC980414 GPIOBRIS 16-bit
  [n] GPIORIS{n} (n=0..7)
0xFC980418 GPIOBMIS 16-bit
  [n] GPIOMIS{n} (n=0..7)
0xFC98041C GPIOBIC 16-bit
  [n] GPIOIC{n} (n=0..7)
0xFC980420 GPIOBAFSEL 16-bit
  [n] GPIOAFSEL{n} (n=0..7)
{0xFC980FE0+4i} GPIOBPeriphID{i} 16-bit (i=0..3)
{0xFC980FF0+4i} GPIOBPCellID{i} 16-bit (i=0..3)
0xFCA00000 SCCTRL
  [23] WDogEnOv, [6:3] ModeStatus, [2:0] ModeCtrl
0xFCA00004 SCSYSSTAT
0xFCA00008 SCIMCTRL
  [7] InMdType, [3:1] ItMdCtrl, [0] ItMdEn
0xFCA0000C SCIMSTAT
  [0] ItMdStat
0xFCA00010 SCXTALCTRL
  [18:3] XtalTime, [2] XtalStat, [1] XtalEn, [0] XtalOver
0xFCA00014 SCPLLCTRL
  [27:3] PllTime, [2] PllStat, [1] PllEn, [0] PllOver
{0xFCA00EE0+4i} SCSYSID{i} (i=0..3)
{0xFCA00FE0+4i} SCPeriphID{i} (i=0..3)
{0xFCA00FF0+4i} SCPCellID{i} (i=0..3)
0xFCA80000 SOC_CFG_CTR
  [19] boot_sel, [18] dual_core, [17] nand_disab, [16] nand_16b, [13] full_ras_mode, [11] expi_iobrg_enb, [10] expi_ras_enb, [9] expi_clk_src, [8] expi_itf_enb, [7:6] SoC_applic, [5:0] SoC_cfg
0xFCA80004 DIAG_CFG_CTR
  [15:14] debug_freez, [11] sys_error, [2:0] SoC_dbg
0xFCA80020 PLL_CLK_CFG
  [30:28] mctr_clk_sel, [26:24] pll2_clk_sel, [22:20] pll1_clk_sel, [19] mem_dll_lock, [18] usb_pll_lock, [17] sys_pll2_lock, [16] sys_pll1_lock, [2] pll3_enb_clkout, [1] pll2_enb_clkout, [0] pll1_enb_clkout
0xFCA80024 CORE_CLK_CFG
  [21:20] osci30_div_ratio, [19] osci30_div_en, [18] ras_synt34_clksel, [17:16] hclk_clk2_ratio, [15:14] hclk_clk1_ratio, [13] clk2_divsel, [12] clk1_divsel, [11:10] hclk_divsel, [9:8] pclk_ratio_lwsp, [7:6] pclk_ratio_appl, [5:4] pclk_ratio_basc, [3:2] pclk_ratio_arm2, [1:0] pclk_ratio_arm1
0xFCA80028 PRPH_CLK_CFG
  [n+12] gptmr{n}_freez (n=1..5), [n+7] gptmr{n}_clksel (n=1..5), [7] rtc_disable, [6:5] irda_clksel, [4] uart_clksel, [3:2] clcd_clksel, [1] plltimeen, [0] xtaltimeen
{0xFCA80040+4i} PRSC{i}_CLK_CFG (i=1..3)
  [15:12] presc_n, [11:0] presc_m
0xFCA80050 AMEM_CFG_CTRL
  [31:24] amem_xdiv, [23:16] amem_ydiv, [15] amem_rst, [4] amem_synt_enb, [3:1] amem_clk_sel, [0] amem_clk_enb
0xFCA8005C CLCD_CLK_SYNT
  [31] synt_clk_enb, [30] synt_clkout_sel, [27:16] synt_xdiv, [11:0] synt_ydiv
0xFCA80060 IRDA_CLK_SYNT
  fields as CLCD_CLK_SYNT
0xFCA80064 UART_CLK_SYNT
  fields as CLCD_CLK_SYNT
0xFCA80068 MAC_CLK_SYNT
  fields as CLCD_CLK_SYNT
{0xFCA80068+4i} RAS{i}_CLK_SYNT (i=1..4)
  fields as CLCD_CLK_SYNT
{0xFCA80078+4i} ICM{i}_ARB_CFG (i=1..9)
  [31] mtx_arb_type, [30:28] mxt_rndrb_pry_lyr, [3n+2:3n] mtx_fix_pry_lyr{n} (n=0..7)
0xFCA800A0 DMA_CHN_CFG
  [2n+1:2n] dma_cfg_chan{n:02} (n=0..15)
0xFCA800A4 USB2_PHY_CFG
  [14] rxerror3_usbh2, [13] rxerror2_usbh1, [12] rxerror1_usbdv, [10] phyreset_chn3, [9] phyreset_chn2, [8] phyreset_chn1, [3] usbh_overcur, [1] pll_pwdn, [0] dynamic_pwdn
0xFCA800B0 ICM10_ARB_CFG
  fields as ICM1_ARB_CFG
0xFCA800E0 POWERDOWN_CFG_CTR
  [0] wakeup_fiq_enb
0xFCA800EC COMPCOR_3V3_CFG
  [30:24] rasrc, [22:16] nasrc, [4] sts_ok, [3] accurate, [2] freeze, [1] tq, [0] en
0xFCA800F0 SSTLPAD_CFG_CTR
  [31] lvds_bengup_enb, [19:16] swkey_ddrsel, [15] dram_type, [14] com_ref, [12] pseudo_dif_dis, [11] ndqs_pdn_sel, [10] ndqs_pu_sel, [9] dqs_pdn_sel, [8] dqs_pu_sel, [7] clk_pdn_sel, [6] clk_pu_sel, [5] pdn_sel, [4] pu_sel, [3] drive_mode_s_w, [2] prog_a, [1] prog_b, [0] sstl_sel
0xFCA8011C SYSERR_CFG_CTR
  [28] dma_err, [27] Mem_err, [26] usbh2_err, [25] usbh1_err, [24] usbdv_err, [23] arm2_wdg_err, [22] arm1_wdg_err, [21] expi_eh2hs_err, [20] expi_eh2hm_err, [15] mem_dll_err, [14] usb_pll_err, [13] sys_pll2_err, [12] sys_pll1_err, [10] dma_err_enb, [9] mem_err_enb, [8] usb_err_enb, [7] exp_err_enb, [6] wdg_err_enb, [4] pll_err_enb, [2] int_error, [1] int_error_rst, [0] int_error_enb
